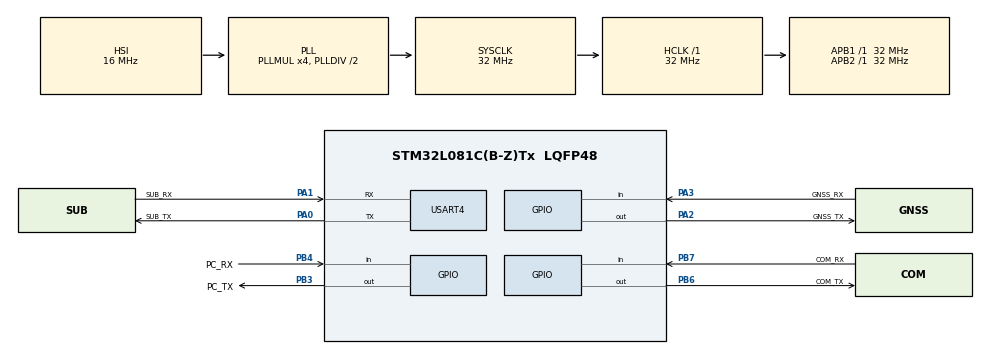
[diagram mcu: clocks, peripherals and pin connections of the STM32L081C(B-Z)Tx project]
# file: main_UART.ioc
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Mcu.Family=STM32L0
Mcu.Name=STM32L081C(B-Z)Tx
Mcu.Package=LQFP48
PA0.GPIO_Label=SUB_TX
PA0.Mode=Asynchronous
PA0.Signal=USART4_TX
PA1.GPIO_Label=SUB_RX
PA1.Mode=Asynchronous
PA1.Signal=USART4_RX
PA13.Mode=Serial_Wire
PA13.Signal=SYS_SWDIO
PA14.Mode=Serial_Wire
PA14.Signal=SYS_SWCLK
PA2.GPIO_Label=GNSS_TX
PA2.GPIO_Speed=GPIO_SPEED_FREQ_VERY_HIGH
PA2.Signal=GPIO_Output
PA3.GPIO_Label=GNSS_RX
PA3.Signal=GPIO_Input
PB3.GPIO_Label=PC_TX
PB3.GPIO_Speed=GPIO_SPEED_FREQ_VERY_HIGH
PB3.Signal=GPIO_Output
PB4.GPIO_Label=PC_RX
PB4.Signal=GPIO_Input
PB6.GPIO_FM6=__NULL
PB6.GPIO_Label=COM_TX
PB6.GPIO_Speed=GPIO_SPEED_FREQ_VERY_HIGH
PB6.Signal=GPIO_Output
PB7.GPIO_Label=COM_RX
PB7.Signal=GPIO_Input
ProjectManager.HeapSize=0x200
ProjectManager.StackSize=0x400
ProjectManager.TargetToolchain=STM32CubeIDE
RCC.AHBFreq_Value=32000000
RCC.APB1Freq_Value=32000000
RCC.APB1TimFreq_Value=32000000
RCC.APB2Freq_Value=32000000
RCC.APB2TimFreq_Value=32000000
RCC.HCLKFreq_Value=32000000
RCC.HSE_VALUE=8000000
RCC.HSI16_VALUE=16000000
RCC.HSI_VALUE=16000000
RCC.LSE_VALUE=32768
RCC.MSI_VALUE=2097000
RCC.PLLMUL=RCC_PLLMUL_4
RCC.SYSCLKFreq_VALUE=32000000
RCC.SYSCLKSource=RCC_SYSCLKSOURCE_PLLCLK
RCC.VCOOutputFreq_Value=64000000
USART4.VirtualMode-Asynchronous=VM_ASYNC
board=custom

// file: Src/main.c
/* USER CODE BEGIN Header */
/**
  ******************************************************************************
  * @file           : main.c
  * @brief          : Main program body
  ******************************************************************************
  * @attention
  *
  * <h2><center>&copy; Copyright (c) 2019 STMicroelectronics.
  * All rights reserved.</center></h2>
  *
  * This software component is licensed by ST under BSD 3-Clause license,
  * the "License"; You may not use this file except in compliance with the
  * License. You may obtain a copy of the License at:
  *                        opensource.org/licenses/BSD-3-Clause
  *
  ******************************************************************************
  */
/* USER CODE END Header */

#include "main.h"

/* USER CODE BEGIN PM */
#define COM  1
#define GNSS 2

#define MODE GNSS //COM or GNSS

/* USER CODE END PM */

UART_HandleTypeDef huart4;

void SystemClock_Config(void);
static void MX_GPIO_Init(void);
static void MX_USART4_UART_Init(void);

int main(void)
{

  /* MCU Configuration--------------------------------------------------------*/

  /* Reset of all peripherals, Initializes the Flash interface and the Systick. */
  HAL_Init();

  /* Configure the system clock */
  SystemClock_Config();

  /* Initialize all configured peripherals */
  MX_GPIO_Init();
  MX_USART4_UART_Init();

  /* Infinite loop */
  while (1)
  {

    /* USER CODE BEGIN 3 */
#if (MODE == COM)
	  HAL_GPIO_WritePin(COM_TX_GPIO_Port	, COM_TX_Pin,	HAL_GPIO_ReadPin(PC_RX_GPIO_Port,	PC_RX_Pin	));
	  HAL_GPIO_WritePin(PC_TX_GPIO_Port		, PC_TX_Pin ,	HAL_GPIO_ReadPin(COM_RX_GPIO_Port,	COM_RX_Pin	));
#else
	  HAL_GPIO_WritePin(GNSS_TX_GPIO_Port	, GNSS_TX_Pin,	HAL_GPIO_ReadPin(PC_RX_GPIO_Port,	PC_RX_Pin));
	  HAL_GPIO_WritePin(PC_TX_GPIO_Port		, PC_TX_Pin	 ,	HAL_GPIO_ReadPin(GNSS_RX_GPIO_Port,	GNSS_RX_Pin));
#endif

  }
  /* USER CODE END 3 */
}

void SystemClock_Config(void)
{
  RCC_OscInitTypeDef RCC_OscInitStruct = {0};
  RCC_ClkInitTypeDef RCC_ClkInitStruct = {0};

  /** Configure the main internal regulator output voltage
  */
  __HAL_PWR_VOLTAGESCALING_CONFIG(PWR_REGULATOR_VOLTAGE_SCALE1);
  /** Initializes the CPU, AHB and APB busses clocks
  */
  RCC_OscInitStruct.OscillatorType = RCC_OSCILLATORTYPE_HSI;
  RCC_OscInitStruct.HSIState = RCC_HSI_ON;
  RCC_OscInitStruct.HSICalibrationValue = RCC_HSICALIBRATION_DEFAULT;
  RCC_OscInitStruct.PLL.PLLState = RCC_PLL_ON;
  RCC_OscInitStruct.PLL.PLLSource = RCC_PLLSOURCE_HSI;
  RCC_OscInitStruct.PLL.PLLMUL = RCC_PLLMUL_4;
  RCC_OscInitStruct.PLL.PLLDIV = RCC_PLLDIV_2;
  if (HAL_RCC_OscConfig(&RCC_OscInitStruct) != HAL_OK)
  {
    Error_Handler();
  }
  /** Initializes the CPU, AHB and APB busses clocks
  */
  RCC_ClkInitStruct.ClockType = RCC_CLOCKTYPE_HCLK|RCC_CLOCKTYPE_SYSCLK
                              |RCC_CLOCKTYPE_PCLK1|RCC_CLOCKTYPE_PCLK2;
  RCC_ClkInitStruct.SYSCLKSource = RCC_SYSCLKSOURCE_PLLCLK;
  RCC_ClkInitStruct.AHBCLKDivider = RCC_SYSCLK_DIV1;
  RCC_ClkInitStruct.APB1CLKDivider = RCC_HCLK_DIV1;
  RCC_ClkInitStruct.APB2CLKDivider = RCC_HCLK_DIV1;

  if (HAL_RCC_ClockConfig(&RCC_ClkInitStruct, FLASH_LATENCY_1) != HAL_OK)
  {
    Error_Handler();
  }
}

static void MX_USART4_UART_Init(void)
{

  huart4.Instance = USART4;
  huart4.Init.BaudRate = 115200;
  huart4.Init.WordLength = UART_WORDLENGTH_8B;
  huart4.Init.StopBits = UART_STOPBITS_1;
  huart4.Init.Parity = UART_PARITY_NONE;
  huart4.Init.Mode = UART_MODE_TX_RX;
  huart4.Init.HwFlowCtl = UART_HWCONTROL_NONE;
  huart4.Init.OverSampling = UART_OVERSAMPLING_16;
  huart4.Init.OneBitSampling = UART_ONE_BIT_SAMPLE_DISABLE;
  huart4.AdvancedInit.AdvFeatureInit = UART_ADVFEATURE_NO_INIT;
  if (HAL_UART_Init(&huart4) != HAL_OK)
  {
    Error_Handler();
  }

}

static void MX_GPIO_Init(void)
{
  GPIO_InitTypeDef GPIO_InitStruct = {0};

  /* GPIO Ports Clock Enable */
  __HAL_RCC_GPIOA_CLK_ENABLE();
  __HAL_RCC_GPIOB_CLK_ENABLE();

  /*Configure GPIO pin Output Level */
  HAL_GPIO_WritePin(GNSS_TX_GPIO_Port, GNSS_TX_Pin, GPIO_PIN_RESET);

  /*Configure GPIO pin Output Level */
  HAL_GPIO_WritePin(GPIOB, PC_TX_Pin|COM_TX_Pin, GPIO_PIN_RESET);

  /*Configure GPIO pin : GNSS_TX_Pin */
  GPIO_InitStruct.Pin = GNSS_TX_Pin;
  GPIO_InitStruct.Mode = GPIO_MODE_OUTPUT_PP;
  GPIO_InitStruct.Pull = GPIO_NOPULL;
  GPIO_InitStruct.Speed = GPIO_SPEED_FREQ_VERY_HIGH;
  HAL_GPIO_Init(GNSS_TX_GPIO_Port, &GPIO_InitStruct);

  /*Configure GPIO pin : GNSS_RX_Pin */
  GPIO_InitStruct.Pin = GNSS_RX_Pin;
  GPIO_InitStruct.Mode = GPIO_MODE_INPUT;
  GPIO_InitStruct.Pull = GPIO_NOPULL;
  HAL_GPIO_Init(GNSS_RX_GPIO_Port, &GPIO_InitStruct);

  /*Configure GPIO pins : PC_TX_Pin COM_TX_Pin */
  GPIO_InitStruct.Pin = PC_TX_Pin|COM_TX_Pin;
  GPIO_InitStruct.Mode = GPIO_MODE_OUTPUT_PP;
  GPIO_InitStruct.Pull = GPIO_NOPULL;
  GPIO_InitStruct.Speed = GPIO_SPEED_FREQ_VERY_HIGH;
  HAL_GPIO_Init(GPIOB, &GPIO_InitStruct);

  /*Configure GPIO pins : PC_RX_Pin COM_RX_Pin */
  GPIO_InitStruct.Pin = PC_RX_Pin|COM_RX_Pin;
  GPIO_InitStruct.Mode = GPIO_MODE_INPUT;
  GPIO_InitStruct.Pull = GPIO_NOPULL;
  HAL_GPIO_Init(GPIOB, &GPIO_InitStruct);

}

void Error_Handler(void)
{
}

/************************ (C) COPYRIGHT STMicroelectronics *****END OF FILE****/
